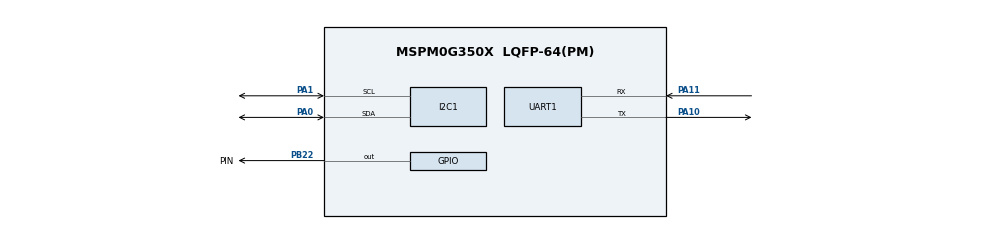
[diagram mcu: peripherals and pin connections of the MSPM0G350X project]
/**
 * @cliArgs --device "MSPM0G350X" --part "Default" --package "LQFP-64(PM)" --product "mspm0_sdk@2.02.00.05"
 * @versions {"tool":"1.21.0+3721"}
 */

/**
 * Import the modules used in this configuration.
 */
const GPIO   = scripting.addModule("/ti/driverlib/GPIO", {}, false);
const GPIO1  = GPIO.addInstance();
const I2C    = scripting.addModule("/ti/driverlib/I2C", {}, false);
const I2C1   = I2C.addInstance();
const SYSCTL = scripting.addModule("/ti/driverlib/SYSCTL");
const UART   = scripting.addModule("/ti/driverlib/UART", {}, false);
const UART1  = UART.addInstance();

/**
 * Write custom configuration values to the imported modules.
 */
const divider9       = system.clockTree["UDIV"];
divider9.divideValue = 2;

const mux4       = system.clockTree["EXHFMUX"];
mux4.inputSelect = "EXHFMUX_XTAL";

const mux8       = system.clockTree["HSCLKMUX"];
mux8.inputSelect = "HSCLKMUX_SYSPLL2X";

const mux12       = system.clockTree["SYSPLLMUX"];
mux12.inputSelect = "zSYSPLLMUX_HFCLK";

const pinFunction4        = system.clockTree["HFXT"];
pinFunction4.inputFreq    = 40;
pinFunction4.enable       = true;
pinFunction4.HFCLKMonitor = true;
pinFunction4.HFXTStartup  = 20;

GPIO1.$name                          = "LED";
GPIO1.associatedPins[0].$name        = "PIN";
GPIO1.associatedPins[0].ioStructure  = "SD";
GPIO1.associatedPins[0].assignedPort = "PORTB";
GPIO1.associatedPins[0].assignedPin  = "22";
GPIO1.associatedPins[0].pin.$assign  = "PB22";

const Board = scripting.addModule("/ti/driverlib/Board", {}, false);

I2C1.$name                             = "I2C_OLED";
I2C1.basicClockSourceDivider           = 4;
I2C1.basicEnableController             = true;
I2C1.basicControllerStandardBusSpeed   = "Fast";
I2C1.basicControllerBusSpeed           = 500000;
I2C1.peripheral.$assign                = "I2C0";
I2C1.peripheral.sdaPin.$assign         = "PA0";
I2C1.peripheral.sclPin.$assign         = "PA1";
I2C1.sdaPinConfig.$name                = "ti_driverlib_gpio_GPIOPinGeneric2";
I2C1.sdaPinConfig.hideOutputInversion  = scripting.forceWrite(false);
I2C1.sdaPinConfig.onlyInternalResistor = scripting.forceWrite(false);
I2C1.sdaPinConfig.passedPeripheralType = scripting.forceWrite("Digital");
I2C1.sclPinConfig.$name                = "ti_driverlib_gpio_GPIOPinGeneric3";
I2C1.sclPinConfig.hideOutputInversion  = scripting.forceWrite(false);
I2C1.sclPinConfig.onlyInternalResistor = scripting.forceWrite(false);
I2C1.sclPinConfig.passedPeripheralType = scripting.forceWrite("Digital");

SYSCTL.forceDefaultClkConfig = true;
SYSCTL.clockTreeEn           = true;
SYSCTL.validateClkStatus     = true;

UART1.$name                        = "UART_0";
UART1.targetBaudRate               = 115200;
UART1.peripheral.$assign           = "UART0";
UART1.peripheral.rxPin.$assign     = "PA11";
UART1.peripheral.txPin.$assign     = "PA10";
UART1.txPinConfig.$name            = "ti_driverlib_gpio_GPIOPinGeneric0";
UART1.txPinConfig.enableConfig     = true;
UART1.txPinConfig.internalResistor = "PULL_UP";
UART1.rxPinConfig.$name            = "ti_driverlib_gpio_GPIOPinGeneric1";
UART1.rxPinConfig.enableConfig     = true;
UART1.rxPinConfig.internalResistor = "PULL_UP";

/**
 * Pinmux solution for unlocked pins/peripherals. This ensures that minor changes to the automatic solver in a future
 * version of the tool will not impact the pinmux you originally saw.  These lines can be completely deleted in order to
 * re-solve from scratch.
 */
pinFunction4.peripheral.$suggestSolution           = "SYSCTL";
pinFunction4.peripheral.hfxInPin.$suggestSolution  = "PA5";
pinFunction4.peripheral.hfxOutPin.$suggestSolution = "PA6";
Board.peripheral.$suggestSolution                  = "DEBUGSS";
Board.peripheral.swclkPin.$suggestSolution         = "PA20";
Board.peripheral.swdioPin.$suggestSolution         = "PA19";
